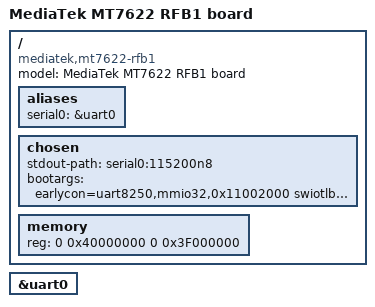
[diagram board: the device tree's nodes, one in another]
/*
 * Copyright (c) 2017 MediaTek Inc.
 * Author: Ming Huang <ming.huang@mediatek.com>
 *	   Sean Wang <sean.wang@mediatek.com>
 *
 * SPDX-License-Identifier: (GPL-2.0 OR MIT)
 */

/dts-v1/;
#include "mt7622.dtsi"

/ {
	model = "MediaTek MT7622 RFB1 board";
	compatible = "mediatek,mt7622-rfb1", "mediatek,mt7622";

	aliases {
		serial0 = &uart0;
	};

	chosen {
		stdout-path = "serial0:115200n8";
		bootargs = "earlycon=uart8250,mmio32,0x11002000 swiotlb=512";
	};

	memory {
		reg = <0 0x40000000 0 0x3F000000>;
	};
};

&uart0 {
	status = "okay";
};
